# LPC43xx register map
File version: 10
CPU: CM4 r0p0, little endian, no MPU, no FPU, 3 interrupt priority bits
Registers are 32-bit, read-write, reset 0x0 unless marked. A register's access mark holds for its fields unless they carry their own. Offsets are from the block's base; [hi:lo] are bit positions; {n}, {i} and the like mark numbered series; 'fields as' and 'values as' point back to an identical list.

## CGU — Clock Generation Unit (CGU)
Base 0x40050000
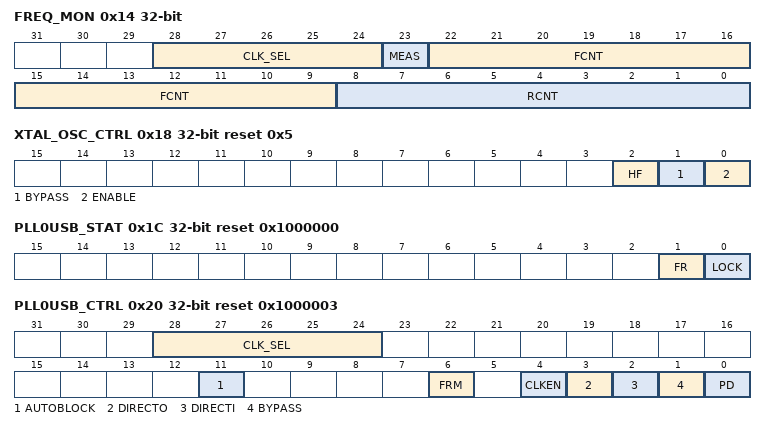
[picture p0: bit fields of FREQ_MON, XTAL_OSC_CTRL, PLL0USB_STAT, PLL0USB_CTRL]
0x14 FREQ_MON — Frequency monitor register
  [28:24] CLK_SEL — Clock-source selection for the clock to be measured. All other values are reserved.
    0=32_KHZ_OSCILLATOR_D (32 kHz oscillator (default)); 1=IRC; 2=ENET_RX_CLK; 3=ENET_TX_CLK; 4=GP_CLKIN; 6=CRYSTAL_OSCILLATOR; 7=PLL0USB; 8=PLL0AUDIO; 9=PLL1; 12=IDIVA; 13=IDIVB; 14=IDIVC; 15=IDIVD; 16=IDIVE
  [23] MEAS — Measure frequency
    0=RCNT_AND_FCNT_DISABL (RCNT and FCNT disabled); 1=FREQUENCY_COUNTERS_S (Frequency counters started)
  [22:9] FCNT — 14-bit selected clock-counter value
  [8:0] RCNT — 9-bit reference clock-counter value
0x18 XTAL_OSC_CTRL reset 0x5 — Crystal oscillator control register
  [2] HF — Select frequency range
    0=LOW (Low. Oscillator low-frequency mode (crystal or external clock source 1 to 20 MHz). Between 15 MHz and 20 MHz, the state of the HF bit is don't care.); 1=HIGH (High. Oscillator high-frequency mode; crystal or external clock source 15 to 25 MHz. Between 15 MHz and 20 MHz, the state of the HF bit is don't care.)
  [1] BYPASS — Configure crystal operation or external-clock input pin XTAL1. Do not change the BYPASS and ENABLE bits in one write-action: this will result in unstable device operation!
    0=CRYSTAL (Crystal. Operation with crystal connected (default).); 1=BYPASS_MODE (Bypass mode. Use this mode when an external clock source is used instead of a crystal.)
  [0] ENABLE — Oscillator-pad enable. Do not change the BYPASS and ENABLE bits in one write-action: this will result in unstable device operation!
    0=ENABLE; 1=POWER_DOWN (Power-down (default))
0x1C PLL0USB_STAT ro reset 0x1000000 — PLL0USB status register
  [1] FR — PLL0 free running indicator
  [0] LOCK — PLL0 lock indicator
0x20 PLL0USB_CTRL reset 0x1000003 — PLL0USB control register
  [28:24] CLK_SEL — Clock source selection. All other values are reserved.
    0=32_KHZ_OSCILLATOR; 1=IRC (IRC (default)); 2=ENET_RX_CLK; 3=ENET_TX_CLK; 4=GP_CLKIN; 6=CRYSTAL_OSCILLATOR; 9=PLL1; 12=IDIVA; 13=IDIVB; 14=IDIVC; 15=IDIVD; 16=IDIVE
  [11] AUTOBLOCK — Block clock automatically during frequency change
    0=DISABLED (Disabled. Autoblocking disabled); 1=ENABLED (Enabled. Autoblocking enabled)
  [6] FRM — Free running mode
  [4] CLKEN — PLL0 clock enable
  [3] DIRECTO — PLL0 direct output
  [2] DIRECTI — PLL0 direct input
  [1] BYPASS — Input clock bypass control
    0=CCO_CLOCK_SENT_TO_PO (CCO clock sent to post-dividers. Use this in normal operation.); 1=PLL0_INPUT_CLOCK_SEN (PLL0 input clock sent to post-dividers (default).)
  [0] PD — PLL0 power down
    0=PLL0_ENABLED; 1=PLL0_POWERED_DOWN
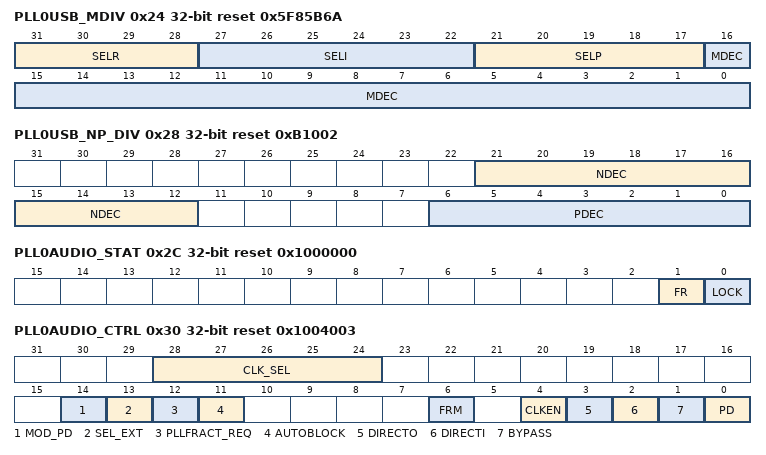
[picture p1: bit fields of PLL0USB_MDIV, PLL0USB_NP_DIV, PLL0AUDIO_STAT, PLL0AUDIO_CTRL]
0x24 PLL0USB_MDIV reset 0x5F85B6A — PLL0USB M-divider register
  [31:28] SELR — Bandwidth select R value; SELR = 0.
  [27:22] SELI — Bandwidth select I value
  [21:17] SELP — Bandwidth select P value
  [16:0] MDEC — Decoded M-divider coefficient value. Select values for the M-divider between 1 and 131071.
0x28 PLL0USB_NP_DIV reset 0xB1002 — PLL0USB N/P-divider register
  [21:12] NDEC — Decoded N-divider coefficient value
  [6:0] PDEC — Decoded P-divider coefficient value
0x2C PLL0AUDIO_STAT ro reset 0x1000000 — PLL0AUDIO status register
  fields as PLL0USB_STAT
0x30 PLL0AUDIO_CTRL reset 0x1004003 — PLL0AUDIO control register
  [28:24] CLK_SEL — Clock source selection. All other values are reserved.
    0=32_KHZ_OSCILLATOR; 1=IRC_DEFAULT; 2=ENET_RX_CLK; 3=ENET_TX_CLK; 4=GP_CLKIN; 6=CRYSTAL_OSCILLATOR; 9=PLL1; 12=IDIVA; 13=IDIVB; 14=IDIVC; 15=IDIVD; 16=IDIVE
  [14] MOD_PD — Sigma-Delta modulator power-down
    0=ENABLED (Enabled. Sigma-Delta modulator enabled); 1=DISABLED (Disabled. Sigma-Delta modulator powered down)
  [13] SEL_EXT — Select fractional divider.
    0=FRAC_ENABLED (FRAC Enabled. Enable fractional divider.); 1=MDEC_ENABLED (MDEC enabled. Fractional divider not used.)
  [12] PLLFRACT_REQ — Fractional PLL word write request. Set this bit to 1 if the fractional divider is enabled in the SEL_EXT bit.
  [11] AUTOBLOCK — Block clock automatically during frequency change
    values as PLL0USB_CTRL.AUTOBLOCK
  [6] FRM — Free running mode
  [4] CLKEN — PLL0 clock enable
  [3] DIRECTO — PLL0 direct output
  [2] DIRECTI — PLL0 direct input
  [1] BYPASS — Input clock bypass control
    values as PLL0USB_CTRL.BYPASS
  [0] PD — PLL0 power down
    0=PLL0_ENABLED; 1=PLL0_POWERED_DOWN
0x34 PLL0AUDIO_MDIV reset 0x5F85B6A — PLL0AUDIO M-divider register
  [16:0] MDEC — Decoded M-divider coefficient value. Select values for the M-divider between 1 and 131071.
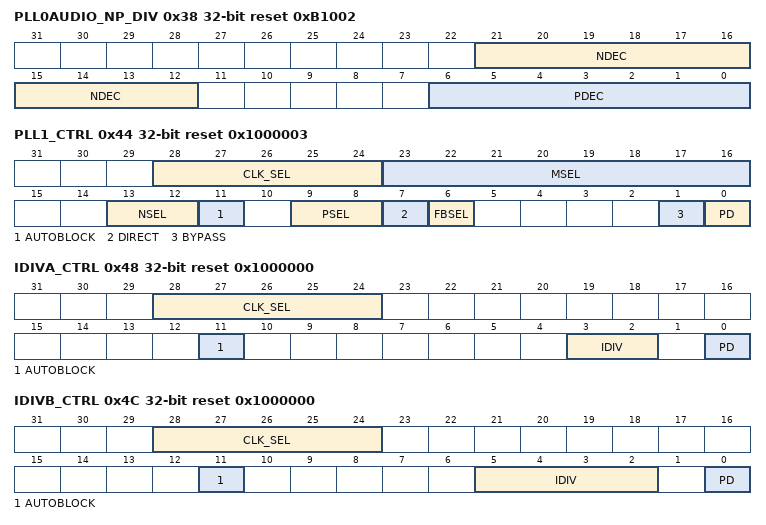
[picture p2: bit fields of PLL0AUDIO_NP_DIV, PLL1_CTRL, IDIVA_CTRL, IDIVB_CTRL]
0x38 PLL0AUDIO_NP_DIV reset 0xB1002 — PLL0AUDIO N/P-divider register
  fields as PLL0USB_NP_DIV
0x3C PLL0AUDIO_FRAC reset 0x200000 — PLL0AUDIO fractional divider register
  [21:0] PLLFRACT_CTRL — PLL fractional divider control word
0x40 PLL1_STAT ro reset 0x1000000 — PLL1 status register
  [0] LOCK — PLL1 lock indicator
0x44 PLL1_CTRL reset 0x1000003 — PLL1 control register
  [28:24] CLK_SEL — Clock-source selection.
    0=32_KHZ_OSCILLATOR; 1=IRC_DEFAULT; 2=ENET_RX_CLK; 3=ENET_TX_CLK; 4=GP_CLKIN; 6=CRYSTAL_OSCILLATOR; 7=PLL0USB; 8=PLL0AUDIO; 12=IDIVA; 13=IDIVB; 14=IDIVC; 15=IDIVD; 16=IDIVE
  [23:16] MSEL — Feedback-divider division ratio (M) 00000000 = 1 00000001 = 2 ... 11111111 = 256
  [13:12] NSEL — Pre-divider division ratio N
    0=1; 1=NEQ2 (2); 2=NEQ3 (3 (default)); 3=4
  [11] AUTOBLOCK — Block clock automatically during frequency change
    values as PLL0USB_CTRL.AUTOBLOCK
  [9:8] PSEL — Post-divider division ratio P. The value applied is 2xP.
    0=1; 1=PEQ2 (2 (default)); 2=PEQ4 (4); 3=8
  [7] DIRECT — PLL direct CCO output
    0=DISABLED; 1=ENABLED
  [6] FBSEL — PLL feedback select.
    0=CCO_OUT (CCO out. CCO output is used as feedback divider input clock.); 1=PLL_OUT (PLL out. PLL output clock (clkout) is used as feedback divider input clock. Use for normal operation.)
  [1] BYPASS — Input clock bypass control
    0=NORMAL (Normal. CCO clock sent to post-dividers. Use for normal operation.); 1=INPUT_CLOCK (Input clock. PLL1 input clock sent to post-dividers (default).)
  [0] PD — PLL1 power down
    0=PLL1_ENABLED; 1=PLL1_POWERED_DOWN
0x48 IDIVA_CTRL reset 0x1000000 — Integer divider A control register
  [28:24] CLK_SEL — Clock source selection. All other values are reserved.
    0=32_KHZ_OSCILLATOR; 1=IRC (IRC (default)); 2=ENET_RX_CLK; 3=ENET_TX_CLK; 4=GP_CLKIN; 6=CRYSTAL_OSCILLATOR; 7=PLL0USB; 8=PLL0AUDIO; 9=PLL1
  [11] AUTOBLOCK — Block clock automatically during frequency change
    values as PLL0USB_CTRL.AUTOBLOCK
  [3:2] IDIV — Integer divider A divider values (1/(IDIV + 1))
    0=DIV1 (1 (default)); 1=DIV2 (2); 2=DIV3 (3); 3=DIV4 (4)
  [0] PD — Integer divider A power down
    0=ENABLED (Enabled. IDIVA enabled (default)); 1=POWER_DOWN
0x4C IDIVB_CTRL reset 0x1000000 — Integer divider B control register
  [28:24] CLK_SEL — Clock-source selection. All other values are reserved.
    0=32_KHZ_OSCILLATOR; 1=IRC_DEFAULT; 2=ENET_RX_CLK; 3=ENET_TX_CLK; 4=GP_CLKIN; 6=CRYSTAL_OSCILLATOR; 8=PLL0AUDIO; 9=PLL1; 12=IDIVA
  [11] AUTOBLOCK — Block clock automatically during frequency change
    values as PLL0USB_CTRL.AUTOBLOCK
  [5:2] IDIV — Integer divider B, C, D divider values (1/(IDIV + 1)) 0000 = 1 (default) 0001 = 2 ... 1111 = 16
  [0] PD — Integer divider power down
    0=ENABLED (Enabled. IDIV enabled (default)); 1=POWER_DOWN
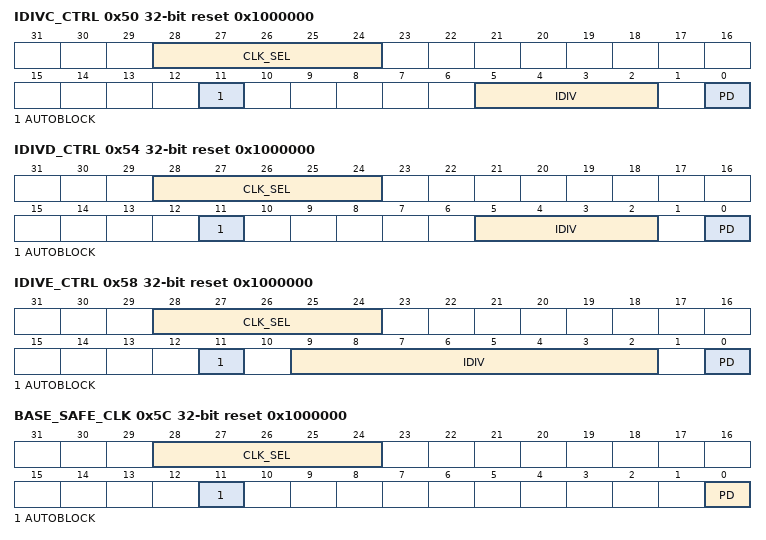
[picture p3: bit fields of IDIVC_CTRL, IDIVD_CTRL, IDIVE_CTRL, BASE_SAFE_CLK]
0x50 IDIVC_CTRL reset 0x1000000 — Integer divider C control register
  fields as IDIVB_CTRL
0x54 IDIVD_CTRL reset 0x1000000 — Integer divider D control register
  fields as IDIVB_CTRL
0x58 IDIVE_CTRL reset 0x1000000 — Integer divider E control register
  [28:24] CLK_SEL — Clock-source selection. All other values are reserved.
    values as IDIVB_CTRL.CLK_SEL
  [11] AUTOBLOCK — Block clock automatically during frequency change
    values as PLL0USB_CTRL.AUTOBLOCK
  [9:2] IDIV — Integer divider E divider values (1/(IDIV + 1)) 00000000 = 1 (default) 00000001 = 2 ... 111111111 = 256
  [0] PD — Integer divider power down
    0=ENABLED (Enabled. IDIV enabled (default)); 1=POWER_DOWN
0x5C BASE_SAFE_CLK ro reset 0x1000000 — Output stage 0 control register for base clock BASE_SAFE_CLK
  [28:24] CLK_SEL — Clock source selection. All other values are reserved.
    1=IRC_DEFAULT
  [11] AUTOBLOCK — Block clock automatically during frequency change
    values as PLL0USB_CTRL.AUTOBLOCK
  [0] PD — Output stage power down
    0=ENABLED (Enabled. Output stage enabled (default)); 1=POWER_DOWN
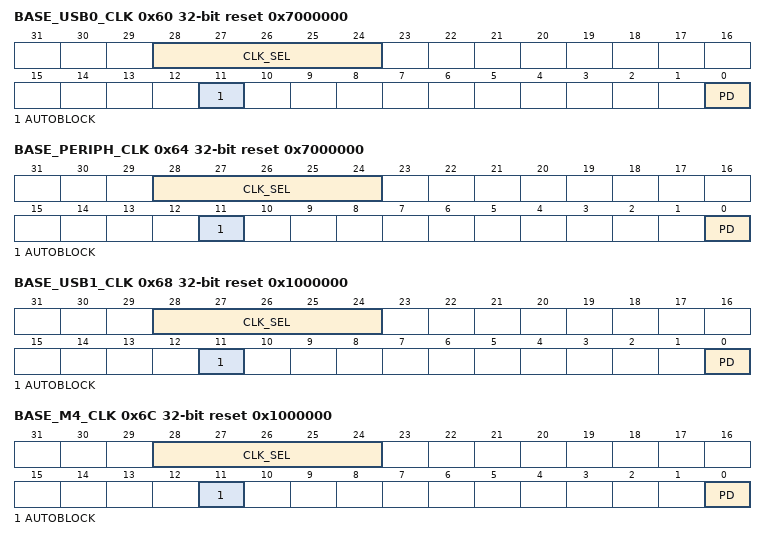
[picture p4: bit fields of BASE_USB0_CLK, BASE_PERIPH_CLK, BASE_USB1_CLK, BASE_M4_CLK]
0x60 BASE_USB0_CLK reset 0x7000000 — Output stage 1 control register for base clock BASE_USB0_CLK
  [28:24] CLK_SEL — Clock-source selection.
    7=PLL0USB (PLL0USB (default))
  [11] AUTOBLOCK — Block clock automatically during frequency change
    values as PLL0USB_CTRL.AUTOBLOCK
  [0] PD — Output stage power down
    values as BASE_SAFE_CLK.PD
0x64 BASE_PERIPH_CLK reset 0x7000000 — Output stage 2 control register for base clock BASE_PERIPH_CLK
  [28:24] CLK_SEL — Clock source selection. All other values are reserved.
    0=32_KHZ_OSCILLATOR; 1=IRC_DEFAULT; 2=ENET_RX_CLK; 3=ENET_TX_CLK; 4=GP_CLKIN; 6=CRYSTAL_OSCILLATOR; 8=PLL0AUDIO; 9=PLL1; 12=IDIVA; 13=IDIVB; 14=IDIVC; 15=IDIVD; 16=IDIVE
  [11] AUTOBLOCK — Block clock automatically during frequency change
    values as PLL0USB_CTRL.AUTOBLOCK
  [0] PD — Output stage power down
    values as BASE_SAFE_CLK.PD
0x68 BASE_USB1_CLK reset 0x1000000 — Output stage 3 control register for base clock BASE_USB1_CLK
  [28:24] CLK_SEL — Clock source selection. All other values are reserved.
    0=32_KHZ_OSCILLATOR; 1=IRC (IRC (default)); 2=ENET_RX_CLK; 3=ENET_TX_CLK; 4=GP_CLKIN; 6=CRYSTAL_OSCILLATOR; 7=PLL0USB; 8=PLL0AUDIO; 9=PLL1; 12=IDIVA; 13=IDIVB; 14=IDIVC; 15=IDIVD; 16=IDIVE
  [11] AUTOBLOCK — Block clock automatically during frequency change
    values as PLL0USB_CTRL.AUTOBLOCK
  [0] PD — Output stage power down
    values as BASE_SAFE_CLK.PD
0x6C BASE_M4_CLK reset 0x1000000 — Output stage BASE_M4_CLK control register
  [28:24] CLK_SEL — Clock source selection. All other values are reserved.
    0=32_KHZ_OSCILLATOR; 1=IRC_DEFAULT; 2=ENET_RX_CLK; 3=ENET_TX_CLK; 4=GP_CLKIN; 6=CRYSTAL_OSCILLATOR; 8=PLL0_FOR_AUDIO; 9=PLL1; 12=IDIVA; 13=IDIVB; 14=IDIVC; 15=IDIVD; 16=IDIVE
  [11] AUTOBLOCK — Block clock automatically during frequency change
    values as PLL0USB_CTRL.AUTOBLOCK
  [0] PD — Output stage power down
    0=OUTPUT_STAGE_ENABLED (Output stage enabled (default)); 1=POWER_DOWN
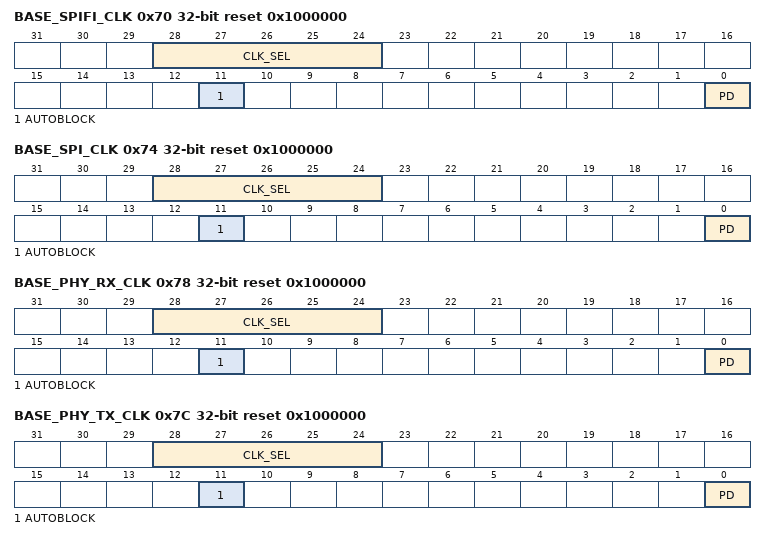
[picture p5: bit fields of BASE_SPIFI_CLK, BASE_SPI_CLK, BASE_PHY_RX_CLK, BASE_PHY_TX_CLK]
0x70 BASE_SPIFI_CLK reset 0x1000000 — Output stage BASE_SPIFI_CLK control register
  fields as BASE_M4_CLK
0x74 BASE_SPI_CLK reset 0x1000000 — Output stage BASE_SPI_CLK control register
  fields as BASE_M4_CLK
0x78 BASE_PHY_RX_CLK reset 0x1000000 — Output stage BASE_PHY_RX_CLK control register
  fields as BASE_M4_CLK
0x7C BASE_PHY_TX_CLK reset 0x1000000 — Output stage BASE_PHY_TX_CLK control register
  fields as BASE_M4_CLK
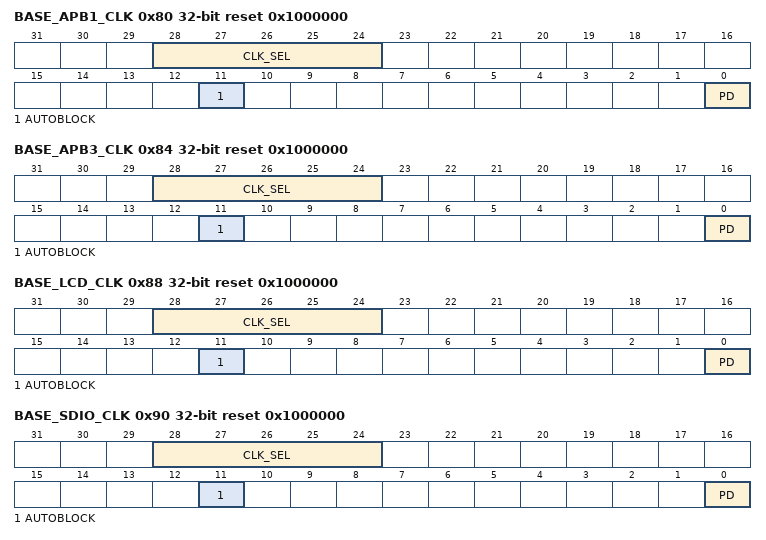
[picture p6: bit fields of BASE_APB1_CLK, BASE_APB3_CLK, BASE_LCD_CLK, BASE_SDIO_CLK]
0x80 BASE_APB1_CLK reset 0x1000000 — Output stage BASE_APB1_CLK control register
  fields as BASE_M4_CLK
0x84 BASE_APB3_CLK reset 0x1000000 — Output stage BASE_APB3_CLK control register
  fields as BASE_M4_CLK
0x88 BASE_LCD_CLK reset 0x1000000 — Output stage BASE_LCD_CLK control register
  fields as BASE_M4_CLK
0x90 BASE_SDIO_CLK reset 0x1000000 — Output stage BASE_SDIO_CLK control register
  fields as BASE_M4_CLK
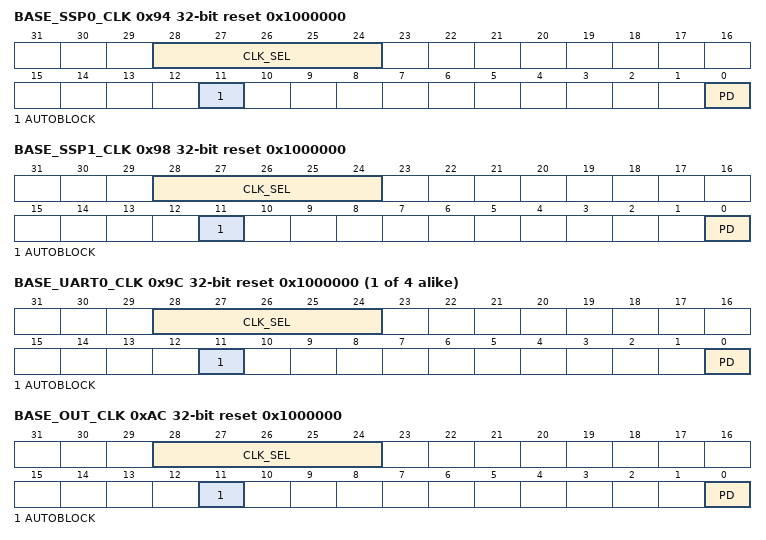
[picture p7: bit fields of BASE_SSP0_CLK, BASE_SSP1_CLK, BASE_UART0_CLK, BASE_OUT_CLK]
0x94 BASE_SSP0_CLK reset 0x1000000 — Output stage BASE_SSP0_CLK control register
  fields as BASE_M4_CLK
0x98 BASE_SSP1_CLK reset 0x1000000 — Output stage BASE_SSP1_CLK control register
  fields as BASE_M4_CLK
{0x9C+4i} BASE_UART{i}_CLK reset 0x1000000 (i=0..3) — Output stage BASE_UART{i}_CLK control register
  fields as BASE_M4_CLK
0xAC BASE_OUT_CLK reset 0x1000000 — Output stage 20 control register for base clock BASE_OUT_CLK
  [28:24] CLK_SEL — Clock-source selection.
    0=32_KHZ_OSCILLATOR; 1=IRC_DEFAULT; 2=ENET_RX_CLK; 3=ENET_TX_CLK; 4=GP_CLKIN; 6=CRYSTAL_OSCILLATOR; 7=PLL0_FOR_USB; 8=PLL0_FOR_AUDIO; 9=PLL1; 12=IDIVA; 13=IDIVB; 14=IDIVC; 15=IDIVD; 16=IDIVE
  [11] AUTOBLOCK — Block clock automatically during frequency change
    0=AUTOBLOCKING_DISABLE (Autoblocking disabled); 1=AUTOBLOCKING_ENABLED
  [0] PD — Output stage power down
    values as BASE_M4_CLK.PD
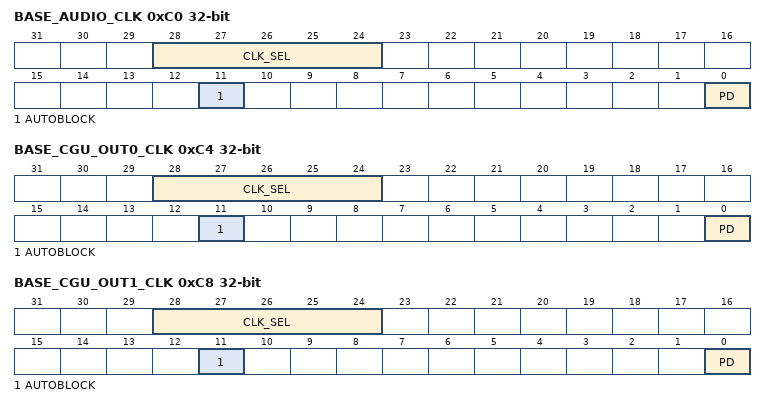
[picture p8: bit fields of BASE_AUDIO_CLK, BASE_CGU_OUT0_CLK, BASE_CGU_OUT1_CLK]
0xC0 BASE_AUDIO_CLK reset not defined — Output stage 25 control register for base clock BASE_AUDIO_CLK
  [28:24] CLK_SEL — Clock-source selection.
    values as BASE_M4_CLK.CLK_SEL
  [11] AUTOBLOCK — Block clock automatically during frequency change
    values as BASE_OUT_CLK.AUTOBLOCK
  [0] PD — Output stage power down
    values as BASE_M4_CLK.PD
0xC4 BASE_CGU_OUT0_CLK reset not defined — Output stage 25 control register for base clock BASE_CGU_OUT0_CLK
  fields as BASE_AUDIO_CLK
0xC8 BASE_CGU_OUT1_CLK reset not defined — Output stage 25 control register for base clock BASE_CGU_OUT1_CLK
  fields as BASE_AUDIO_CLK
